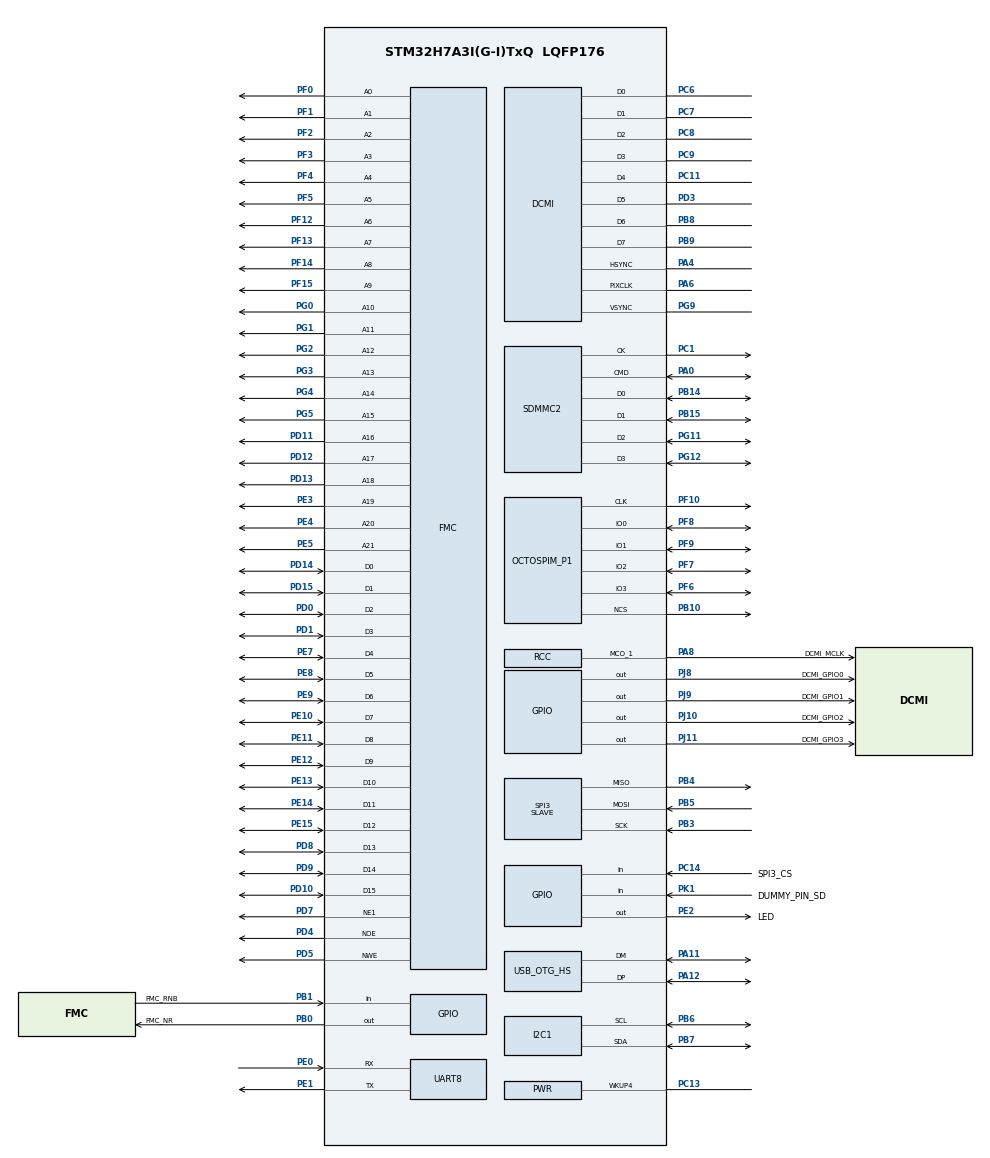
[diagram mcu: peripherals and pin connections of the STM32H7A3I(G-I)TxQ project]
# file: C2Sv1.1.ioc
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CORTEX_M7.AccessPermission_Spec=MPU_REGION_FULL_ACCESS
CORTEX_M7.BaseAddress_Spec=0x60000000
CORTEX_M7.CPU_ICache=Enabled
CORTEX_M7.DisableExec_Spec=MPU_INSTRUCTION_ACCESS_ENABLE
CORTEX_M7.IsBufferable_Spec=MPU_ACCESS_NOT_BUFFERABLE
CORTEX_M7.Size_Spec=MPU_REGION_SIZE_8MB
CORTEX_M7.SubRegionDisable_Spec=0x00
CORTEX_M7.default_mode_Activation=1
DCMI.PCKPolarity=DCMI_PCKPOLARITY_RISING
DCMI.VSPolarity=DCMI_VSPOLARITY_HIGH
Dma.DCMI.0.Direction=DMA_PERIPH_TO_MEMORY
Dma.DCMI.0.EventEnable=DISABLE
Dma.DCMI.0.FIFOMode=DMA_FIFOMODE_ENABLE
Dma.DCMI.0.FIFOThreshold=DMA_FIFO_THRESHOLD_FULL
Dma.DCMI.0.Instance=DMA1_Stream0
Dma.DCMI.0.MemBurst=DMA_MBURST_SINGLE
Dma.DCMI.0.MemDataAlignment=DMA_MDATAALIGN_WORD
Dma.DCMI.0.MemInc=DMA_MINC_ENABLE
Dma.DCMI.0.Mode=DMA_CIRCULAR
Dma.DCMI.0.PeriphBurst=DMA_PBURST_SINGLE
Dma.DCMI.0.PeriphDataAlignment=DMA_PDATAALIGN_WORD
Dma.DCMI.0.PeriphInc=DMA_PINC_DISABLE
Dma.DCMI.0.Polarity=HAL_DMAMUX_REQ_GEN_RISING
Dma.DCMI.0.Priority=DMA_PRIORITY_VERY_HIGH
Dma.DCMI.0.RequestNumber=1
Dma.DCMI.0.SignalID=NONE
Dma.DCMI.0.SyncEnable=DISABLE
Dma.DCMI.0.SyncPolarity=HAL_DMAMUX_SYNC_NO_EVENT
Dma.DCMI.0.SyncRequestNumber=1
Dma.DCMI.0.SyncSignalID=NONE
Dma.Request0=DCMI
FATFS.BSP.number=1
FATFS._MAX_SS=512
FATFS._USE_LFN=2
FATFS0.BSP.STBoard=false
FATFS0.BSP.api=Unknown
FATFS0.BSP.instance=PK1
FATFS0.BSP.ip=GPIO
FATFS0.BSP.mode=Input
FATFS0.BSP.name=Detect_SDIO
FATFS0.BSP.solution=PK1
FMC.WriteOperation1=FMC_WRITE_OPERATION_DISABLE
FREERTOS.Tasks01=defaultTask,24,128,StartDefaultTask,Default,NULL,Dynamic,NULL,NULL;comms,32,768,commsTask,Default,NULL,Dynamic,NULL,NULL;housekeeping,24,512,housekeepingTask,Default,NULL,Dynamic,NULL,NULL;imaging,16,1024,imagingTask,Default,NULL,Dynamic,NULL,NULL;imageReq,8,128,imageHkReqTask,Default,NULL,Dynamic,NULL,NULL
FREERTOS.configCHECK_FOR_STACK_OVERFLOW=2
FREERTOS.configTOTAL_HEAP_SIZE=64000
FREERTOS.configUSE_MALLOC_FAILED_HOOK=1
FREERTOS.configUSE_NEWLIB_REENTRANT=1
I2C1.Timing=0x10808DD3
JPEG.JPEG_RGB_FORMAT=JPEG_RGB565
JPEG.USE_JPEG_DECODER=0
Mcu.Family=STM32H7
Mcu.Name=STM32H7A3I(G-I)TxQ
Mcu.Package=LQFP176
NVIC.DCMI_PSSI_IRQn=true\:6\:0\:true\:false\:true\:true\:true\:true\:true
NVIC.DMA1_Stream0_IRQn=true\:6\:0\:true\:false\:true\:true\:false\:true\:true
NVIC.JPEG_IRQn=true\:7\:0\:true\:false\:true\:true\:true\:true\:true
NVIC.OTG_HS_IRQn=true\:7\:0\:true\:false\:true\:true\:false\:true\:true
NVIC.PriorityGroup=NVIC_PRIORITYGROUP_4
NVIC.SDMMC2_IRQn=true\:5\:0\:false\:false\:true\:true\:true\:true\:true
NVIC.SPI3_IRQn=true\:5\:0\:false\:false\:true\:true\:true\:true\:true
NVIC.TIM17_IRQn=true\:5\:0\:false\:false\:true\:false\:true\:true\:true
NVIC.TIM1_UP_IRQn=true\:15\:0\:false\:false\:true\:false\:false\:true\:true
NVIC.TimeBase=TIM1_UP_IRQn
NVIC.TimeBaseIP=TIM1
OCTOSPI1.ChipSelectHighTime=3
OCTOSPI1.ClockPrescaler=64
OCTOSPI1.DeviceSize=24
OCTOSPI1.SampleShifting=HAL_OSPI_SAMPLE_SHIFTING_NONE
PA0.GPIO_PuPd=GPIO_PULLUP
PA0.GPIO_Speed_High_Default=GPIO_SPEED_FREQ_VERY_HIGH
PA0.Mode=SD_4_bits_Wide_bus
PA0.Signal=SDMMC2_CMD
PA11.Mode=Device_Only_FS
PA11.Signal=USB_OTG_HS_DM
PA12.Mode=Device_Only_FS
PA12.Signal=USB_OTG_HS_DP
PA13.Mode=Serial_Wire
PA13.Signal=DEBUG_JTMS-SWDIO
PA14.Mode=Serial_Wire
PA14.Signal=DEBUG_JTCK-SWCLK
PA4.GPIO_PuPd=GPIO_PULLDOWN
PA4.GPIO_Speed=GPIO_SPEED_FREQ_VERY_HIGH
PA4.Mode=Slave_8_bits_External_Synchro
PA4.Signal=DCMI_HSYNC
PA6.GPIO_PuPd=GPIO_PULLDOWN
PA6.GPIO_Speed=GPIO_SPEED_FREQ_VERY_HIGH
PA6.Mode=Slave_8_bits_External_Synchro
PA6.Signal=DCMI_PIXCLK
PA8.GPIO_Label=DCMI_MCLK
PA8.Mode=Clock-out-1
PA8.Signal=RCC_MCO_1
PB0.GPIO_Label=FMC_NR
PB0.Signal=GPIO_Output
PB1.GPIO_Label=FMC_RNB
PB1.GPIO_PuPd=GPIO_PULLUP
PB1.Signal=GPIO_Input
PB10.Mode=OCTOSPI1_Port1_NCS
PB10.Signal=OCTOSPIM_P1_NCS
PB14.GPIO_PuPd=GPIO_PULLUP
PB14.GPIO_Speed_High_Default=GPIO_SPEED_FREQ_VERY_HIGH
PB14.Mode=SD_4_bits_Wide_bus
PB14.Signal=SDMMC2_D0
PB15.GPIO_PuPd=GPIO_PULLUP
PB15.GPIO_Speed_High_Default=GPIO_SPEED_FREQ_VERY_HIGH
PB15.Mode=SD_4_bits_Wide_bus
PB15.Signal=SDMMC2_D1
PB3.Mode=Full_Duplex_Slave
PB3.Signal=SPI3_SCK
PB4.Mode=Full_Duplex_Slave
PB4.Signal=SPI3_MISO
PB5.Mode=Full_Duplex_Slave
PB5.Signal=SPI3_MOSI
PB6.GPIO_Pu=GPIO_PULLUP
PB6.Mode=I2C
PB6.Signal=I2C1_SCL
PB7.GPIO_Pu=GPIO_PULLUP
PB7.Mode=I2C
PB7.Signal=I2C1_SDA
PB8.GPIO_PuPd=GPIO_PULLDOWN
PB8.GPIO_Speed=GPIO_SPEED_FREQ_VERY_HIGH
PB8.Mode=Slave_8_bits_External_Synchro
PB8.Signal=DCMI_D6
PB9.GPIO_PuPd=GPIO_PULLDOWN
PB9.GPIO_Speed=GPIO_SPEED_FREQ_VERY_HIGH
PB9.Mode=Slave_8_bits_External_Synchro
PB9.Signal=DCMI_D7
PC1.GPIO_PuPd=GPIO_PULLUP
PC1.GPIO_Speed_High_Default=GPIO_SPEED_FREQ_VERY_HIGH
PC1.Mode=SD_4_bits_Wide_bus
PC1.Signal=SDMMC2_CK
PC11.GPIO_PuPd=GPIO_PULLDOWN
PC11.GPIO_Speed=GPIO_SPEED_FREQ_VERY_HIGH
PC11.Mode=Slave_8_bits_External_Synchro
PC11.Signal=DCMI_D4
PC13.Mode=WakeUp4
PC13.Signal=PWR_WKUP4
PC14-OSC32_IN.GPIO_Label=SPI3_CS
PC14-OSC32_IN.Signal=GPIO_Input
PC6.GPIO_PuPd=GPIO_PULLDOWN
PC6.GPIO_Speed=GPIO_SPEED_FREQ_VERY_HIGH
PC6.Mode=Slave_8_bits_External_Synchro
PC6.Signal=DCMI_D0
PC7.GPIO_PuPd=GPIO_PULLDOWN
PC7.GPIO_Speed=GPIO_SPEED_FREQ_VERY_HIGH
PC7.Mode=Slave_8_bits_External_Synchro
PC7.Signal=DCMI_D1
PC8.GPIO_PuPd=GPIO_PULLDOWN
PC8.GPIO_Speed=GPIO_SPEED_FREQ_VERY_HIGH
PC8.Mode=Slave_8_bits_External_Synchro
PC8.Signal=DCMI_D2
PC9.GPIO_PuPd=GPIO_PULLDOWN
PC9.GPIO_Speed=GPIO_SPEED_FREQ_VERY_HIGH
PC9.Mode=Slave_8_bits_External_Synchro
PC9.Signal=DCMI_D3
PD0.Signal=FMC_D2_DA2
PD1.Signal=FMC_D3_DA3
PD10.Signal=FMC_D15_DA15
PD11.Signal=FMC_A16_CLE
PD12.Signal=FMC_A17_ALE
PD13.Signal=FMC_A18
PD14.Signal=FMC_D0_DA0
PD15.Signal=FMC_D1_DA1
PD2.GPIO_PuPd=GPIO_PULLDOWN
PD2.GPIO_Speed=GPIO_SPEED_FREQ_VERY_HIGH
PD2.Signal=DCMI_D11
PD3.GPIO_PuPd=GPIO_PULLDOWN
PD3.GPIO_Speed=GPIO_SPEED_FREQ_VERY_HIGH
PD3.Mode=Slave_8_bits_External_Synchro
PD3.Signal=DCMI_D5
PD4.Signal=FMC_NOE
PD5.Signal=FMC_NWE
PD7.Mode=NorPsramChipSelect1_1
PD7.Signal=FMC_NE1
PD8.Signal=FMC_D13_DA13
PD9.Signal=FMC_D14_DA14
PE0.Mode=Asynchronous
PE0.Signal=UART8_RX
PE1.Mode=Asynchronous
PE1.Signal=UART8_TX
PE10.Signal=FMC_D7_DA7
PE11.Signal=FMC_D8_DA8
PE12.Signal=FMC_D9_DA9
PE13.Signal=FMC_D10_DA10
PE14.Signal=FMC_D11_DA11
PE15.Signal=FMC_D12_DA12
PE2.GPIO_Label=LED
PE2.Signal=GPIO_Output
PE3.Signal=FMC_A19
PE4.Signal=FMC_A20
PE5.Signal=FMC_A21
PE7.Signal=FMC_D4_DA4
PE8.Signal=FMC_D5_DA5
PE9.Signal=FMC_D6_DA6
PF0.Signal=FMC_A0
PF1.Signal=FMC_A1
PF10.Mode=O1_P1_CLK
PF10.Signal=OCTOSPIM_P1_CLK
PF12.Signal=FMC_A6
PF13.Signal=FMC_A7
PF14.Signal=FMC_A8
PF15.Signal=FMC_A9
PF2.Signal=FMC_A2
PF3.Signal=FMC_A3
PF4.Signal=FMC_A4
PF5.Signal=FMC_A5
PF6.Mode=OCTOSPI1_IOL_Port1L
PF6.Signal=OCTOSPIM_P1_IO3
PF7.Mode=OCTOSPI1_IOL_Port1L
PF7.Signal=OCTOSPIM_P1_IO2
PF8.Mode=OCTOSPI1_IOL_Port1L
PF8.Signal=OCTOSPIM_P1_IO0
PF9.Mode=OCTOSPI1_IOL_Port1L
PF9.Signal=OCTOSPIM_P1_IO1
PG0.Signal=FMC_A10
PG1.Signal=FMC_A11
PG11.GPIO_PuPd=GPIO_PULLUP
PG11.GPIO_Speed_High_Default=GPIO_SPEED_FREQ_VERY_HIGH
PG11.Mode=SD_4_bits_Wide_bus
PG11.Signal=SDMMC2_D2
PG12.GPIO_PuPd=GPIO_PULLUP
PG12.GPIO_Speed_High_Default=GPIO_SPEED_FREQ_VERY_HIGH
PG12.Mode=SD_4_bits_Wide_bus
PG12.Signal=SDMMC2_D3
PG2.Signal=FMC_A12
PG3.Signal=FMC_A13
PG4.Signal=FMC_A14_BA0
PG5.Signal=FMC_A15_BA1
PG6.Signal=DCMI_D12
PG7.Signal=DCMI_D13
PG9.GPIO_PuPd=GPIO_PULLDOWN
PG9.GPIO_Speed=GPIO_SPEED_FREQ_VERY_HIGH
PG9.Mode=Slave_8_bits_External_Synchro
PG9.Signal=DCMI_VSYNC
PH0-OSC_IN.Mode=HSE-External-Clock-Source
PH0-OSC_IN.Signal=RCC_OSC_IN
PJ10.GPIO_Label=DCMI_GPIO2
PJ10.Signal=GPIO_Output
PJ11.GPIO_Label=DCMI_GPIO3
PJ11.Signal=GPIO_Output
PJ8.GPIO_Label=DCMI_GPIO0
PJ8.Signal=GPIO_Output
PJ9.GPIO_Label=DCMI_GPIO1
PJ9.Signal=GPIO_Output
PK1.GPIO_Label=DUMMY_PIN_SD
PK1.GPIO_PuPd=GPIO_PULLDOWN
PK1.Signal=GPIO_Input
ProjectManager.HeapSize=0x200
ProjectManager.StackSize=0x400
ProjectManager.TargetToolchain=STM32CubeIDE
RCC.ADCFreq_Value=132000000
RCC.APB1Freq_Value=140000000
RCC.APB2Freq_Value=140000000
RCC.APB3Freq_Value=140000000
RCC.APB4Freq_Value=140000000
RCC.CDPPRE=RCC_APB3_DIV2
RCC.CDPPRE1=RCC_APB1_DIV2
RCC.CDPPRE2=RCC_APB2_DIV2
RCC.CortexFreq_Value=280000000
RCC.DIVM1=3
RCC.DIVM2=2
RCC.DIVM3=2
RCC.DIVN1=70
RCC.DIVN2=11
RCC.DIVN3=12
RCC.DIVP2=1
RCC.DIVP3=1
RCC.DIVQ2=1
RCC.DIVQ3=3
RCC.DIVR2=1
RCC.EnbaleCSS=true
RCC.FMCCLockSelection=RCC_FMCCLKSOURCE_PLL2
RCC.HCLKFreq_Value=280000000
RCC.I2C123CLockSelection=RCC_I2C123CLKSOURCE_PLL3
RCC.PLL2FRACN=0
RCC.PLL3FRACN=0
RCC.PLLFRACN=0
RCC.PLLSourceVirtual=RCC_PLLSOURCE_HSE
RCC.PWR_Regulator_Voltage_Scale=PWR_REGULATOR_VOLTAGE_SCALE0
RCC.RCC_MCO1Source=RCC_MCO1SOURCE_HSE
RCC.SDMMC1CLockSelection=RCC_SDMMCCLKSOURCE_PLL2
RCC.SRDPPRE=RCC_APB4_DIV2
RCC.SYSCLKFreq_VALUE=280000000
RCC.SYSCLKSource=RCC_SYSCLKSOURCE_PLLCLK
RCC.SupplySource=PWR_LDO_SUPPLY
RCC.USBCLockSelection=RCC_USBCLKSOURCE_PLL3
RCC.USBFreq_Value=48000000
SDMMC2.ClockDiv=8
SH.FMC_A0.0=FMC_A0,22b-a1
SH.FMC_A1.0=FMC_A1,22b-a1
SH.FMC_A10.0=FMC_A10,22b-a1
SH.FMC_A11.0=FMC_A11,22b-a1
SH.FMC_A12.0=FMC_A12,22b-a1
SH.FMC_A13.0=FMC_A13,22b-a1
SH.FMC_A14_BA0.0=FMC_A14,22b-a1
SH.FMC_A15_BA1.0=FMC_A15,22b-a1
SH.FMC_A16_CLE.0=FMC_A16,22b-a1
SH.FMC_A17_ALE.0=FMC_A17,22b-a1
SH.FMC_A18.0=FMC_A18,22b-a1
SH.FMC_A19.0=FMC_A19,22b-a1
SH.FMC_A2.0=FMC_A2,22b-a1
SH.FMC_A20.0=FMC_A20,22b-a1
SH.FMC_A21.0=FMC_A21,22b-a1
SH.FMC_A3.0=FMC_A3,22b-a1
SH.FMC_A4.0=FMC_A4,22b-a1
SH.FMC_A5.0=FMC_A5,22b-a1
SH.FMC_A6.0=FMC_A6,22b-a1
SH.FMC_A7.0=FMC_A7,22b-a1
SH.FMC_A8.0=FMC_A8,22b-a1
SH.FMC_A9.0=FMC_A9,22b-a1
SH.FMC_D0_DA0.0=FMC_D0,16b-d1
SH.FMC_D10_DA10.0=FMC_D10,16b-d1
SH.FMC_D11_DA11.0=FMC_D11,16b-d1
SH.FMC_D12_DA12.0=FMC_D12,16b-d1
SH.FMC_D13_DA13.0=FMC_D13,16b-d1
SH.FMC_D14_DA14.0=FMC_D14,16b-d1
SH.FMC_D15_DA15.0=FMC_D15,16b-d1
SH.FMC_D1_DA1.0=FMC_D1,16b-d1
SH.FMC_D2_DA2.0=FMC_D2,16b-d1
SH.FMC_D3_DA3.0=FMC_D3,16b-d1
SH.FMC_D4_DA4.0=FMC_D4,16b-d1
SH.FMC_D5_DA5.0=FMC_D5,16b-d1
SH.FMC_D6_DA6.0=FMC_D6,16b-d1
SH.FMC_D7_DA7.0=FMC_D7,16b-d1
SH.FMC_D8_DA8.0=FMC_D8,16b-d1
SH.FMC_D9_DA9.0=FMC_D9,16b-d1
SH.FMC_NOE.0=FMC_NOE,NorFlash1
SH.FMC_NWE.0=FMC_NWE,NorFlash1
SPI3.DataSize=SPI_DATASIZE_8BIT
SPI3.Direction=SPI_DIRECTION_2LINES
SPI3.Mode=SPI_MODE_SLAVE
SPI3.VirtualType=VM_SLAVE
TIM17.Period=45-1
TIM17.Prescaler=1
USB_DEVICE.CLASS_NAME_HS=CDC
USB_DEVICE.MANUFACTURER_STRING=Perth Aerosapce Student Team
USB_DEVICE.PRODUCT_STRING_CDC_HS=C2Sv1.1
USB_DEVICE.VirtualMode=Cdc
USB_DEVICE.VirtualModeHS=Cdc_HS
USB_OTG_HS.VirtualMode-Device_Only_FS=Device_Only_FS
VP_FATFS_VS_SDIO.Mode=SDIO
VP_FREERTOS_VS_CMSIS_V2.Mode=CMSIS_V2
VP_JPEG_VS_JPEG.Mode=JPEG_Activate
VP_MEMORYMAP_VS_MEMORYMAP.Mode=CurAppReg
VP_OCTOSPI1_VS_quad.Mode=quad_mode
VP_SYS_VS_tim1.Mode=TIM1
VP_TIM17_VS_ClockSourceINT.Mode=Enable_Timer
VP_TIM17_VS_OPM.Mode=OPM_bit
VP_USB_DEVICE_VS_USB_DEVICE_CDC_HS.Mode=CDC_HS
board=custom

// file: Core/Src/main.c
/* USER CODE BEGIN Header */
/**
  ******************************************************************************
  * @file           : main.c
  * @brief          : Main program body
  ******************************************************************************
  * @attention
  *
  * Copyright (c) 2026 STMicroelectronics.
  * All rights reserved.
  *
  * This software is licensed under terms that can be found in the LICENSE file
  * in the root directory of this software component.
  * If no LICENSE file comes with this software, it is provided AS-IS.
  *
  ******************************************************************************
  */
/* USER CODE END Header */
#include "main.h"
#include "FreeRTOS.h"
#include "cmsis_os2.h"
#include "fatfs.h"
#include "usb_device.h"

/* USER CODE BEGIN Includes */

#include "dashboard.h"
#include "img_jpeg.h"
#include "imaging.h"
#include "comms.h"
#include "config.h"
#include "ina219.h"
#include "ov7670.h"
#include "rgb_led.h"
#include "microSD.h"
#include "task.h"

/* USER CODE END Includes */

DCMI_HandleTypeDef hdcmi;
DMA_HandleTypeDef hdma_dcmi;

I2C_HandleTypeDef hi2c1;

JPEG_HandleTypeDef hjpeg;

OSPI_HandleTypeDef hospi1;

SD_HandleTypeDef hsd2;

SPI_HandleTypeDef hspi3;

TIM_HandleTypeDef htim17;

UART_HandleTypeDef huart8;

NOR_HandleTypeDef hnor1;

/* Definitions for defaultTask */
osThreadId_t defaultTaskHandle;
const osThreadAttr_t defaultTask_attributes = {
  .name = "defaultTask",
  .stack_size = 128 * 4,
  .priority = (osPriority_t) osPriorityNormal,
};
/* Definitions for comms */
osThreadId_t commsHandle;
const osThreadAttr_t comms_attributes = {
  .name = "comms",
  .stack_size = 768 * 4,
  .priority = (osPriority_t) osPriorityAboveNormal,
};
/* Definitions for housekeeping */
osThreadId_t housekeepingHandle;
const osThreadAttr_t housekeeping_attributes = {
  .name = "housekeeping",
  .stack_size = 512 * 4,
  .priority = (osPriority_t) osPriorityNormal,
};
/* Definitions for imaging */
osThreadId_t imagingHandle;
const osThreadAttr_t imaging_attributes = {
  .name = "imaging",
  .stack_size = 1024 * 4,
  .priority = (osPriority_t) osPriorityBelowNormal,
};
/* Definitions for imageReq */
osThreadId_t imageReqHandle;
const osThreadAttr_t imageReq_attributes = {
  .name = "imageReq",
  .stack_size = 128 * 4,
  .priority = (osPriority_t) osPriorityLow,
};
/* USER CODE BEGIN PV */

// --- INA219 ---
CSA_HandleTypeDef csa;

// --- DCMI ---
// Static, not a local in main(): FreeRTOS reuses main()'s stack for
// interrupts once the scheduler starts, so DMA into it would corrupt memory.
// Sized for VGA, the largest frame the dashboard requests (614 KB in AXI SRAM).
ALIGN_32BYTES(uint32_t pBuffer[VGA_IMAGE_SIZE_WORDS]);

// -- IMAGING ---
extern volatile imaging_req_t g_imaging_req;

/* USER CODE END PV */

void SystemClock_Config(void);
void PeriphCommonClock_Config(void);
static void MPU_Config(void);
static void MX_GPIO_Init(void);
static void MX_DMA_Init(void);
static void MX_DCMI_Init(void);
static void MX_FMC_Init(void);
static void MX_I2C1_Init(void);
static void MX_OCTOSPI1_Init(void);
static void MX_SDMMC2_SD_Init(void);
static void MX_SPI3_Init(void);
static void MX_UART8_Init(void);
static void MX_TIM17_Init(void);
static void MX_JPEG_Init(void);
void StartDefaultTask(void *argument);
void commsTask(void *argument);
void housekeepingTask(void *argument);
void imagingTask(void *argument);
void imageHkReqTask(void *argument);

int main(void)
{

  /* MPU Configuration--------------------------------------------------------*/
  MPU_Config();

  /* Enable the CPU Cache */

  /* Enable I-Cache---------------------------------------------------------*/
  SCB_EnableICache();

  /* MCU Configuration--------------------------------------------------------*/

  /* Reset of all peripherals, Initializes the Flash interface and the Systick. */
  HAL_Init();

  /* Configure the system clock */
  SystemClock_Config();

  /* Configure the peripherals common clocks */
  PeriphCommonClock_Config();

  /* Initialize all configured peripherals */
  MX_GPIO_Init();
  MX_DMA_Init();
  MX_DCMI_Init();
  MX_FMC_Init();
  MX_I2C1_Init();
  MX_OCTOSPI1_Init();
  MX_SDMMC2_SD_Init();
  MX_SPI3_Init();
  MX_UART8_Init();
  MX_FATFS_Init();
  MX_TIM17_Init();
  MX_JPEG_Init();

  /* Init scheduler */
  osKernelInitialize();

  /* Create the thread(s) */
  /* creation of defaultTask */
  defaultTaskHandle = osThreadNew(StartDefaultTask, NULL, &defaultTask_attributes);

  /* creation of comms */
  commsHandle = osThreadNew(commsTask, NULL, &comms_attributes);

  /* creation of housekeeping */
  housekeepingHandle = osThreadNew(housekeepingTask, NULL, &housekeeping_attributes);

  /* creation of imaging */
  imagingHandle = osThreadNew(imagingTask, NULL, &imaging_attributes);

  /* creation of imageReq */
  imageReqHandle = osThreadNew(imageHkReqTask, NULL, &imageReq_attributes);

  /* Start scheduler */
  osKernelStart();

  /* We should never get here as control is now taken by the scheduler */

  /* Infinite loop */
  while (1)
  {

  }
}

void SystemClock_Config(void)
{
  RCC_OscInitTypeDef RCC_OscInitStruct = {0};
  RCC_ClkInitTypeDef RCC_ClkInitStruct = {0};

  /*AXI clock gating */
  RCC->CKGAENR = 0xE003FFFF;

  /** Supply configuration update enable
  */
  HAL_PWREx_ConfigSupply(PWR_LDO_SUPPLY);

  /** Configure the main internal regulator output voltage
  */
  __HAL_PWR_VOLTAGESCALING_CONFIG(PWR_REGULATOR_VOLTAGE_SCALE0);

  while(!__HAL_PWR_GET_FLAG(PWR_FLAG_VOSRDY)) {}

  /** Initializes the RCC Oscillators according to the specified parameters
  * in the RCC_OscInitTypeDef structure.
  */
  RCC_OscInitStruct.OscillatorType = RCC_OSCILLATORTYPE_HSE;
  RCC_OscInitStruct.HSEState = RCC_HSE_BYPASS;
  RCC_OscInitStruct.PLL.PLLState = RCC_PLL_ON;
  RCC_OscInitStruct.PLL.PLLSource = RCC_PLLSOURCE_HSE;
  RCC_OscInitStruct.PLL.PLLM = 3;
  RCC_OscInitStruct.PLL.PLLN = 70;
  RCC_OscInitStruct.PLL.PLLP = 2;
  RCC_OscInitStruct.PLL.PLLQ = 2;
  RCC_OscInitStruct.PLL.PLLR = 2;
  RCC_OscInitStruct.PLL.PLLRGE = RCC_PLL1VCIRANGE_3;
  RCC_OscInitStruct.PLL.PLLVCOSEL = RCC_PLL1VCOWIDE;
  RCC_OscInitStruct.PLL.PLLFRACN = 0;
  if (HAL_RCC_OscConfig(&RCC_OscInitStruct) != HAL_OK)
  {
    Error_Handler();
  }

  /** Initializes the CPU, AHB and APB buses clocks
  */
  RCC_ClkInitStruct.ClockType = RCC_CLOCKTYPE_HCLK|RCC_CLOCKTYPE_SYSCLK
                              |RCC_CLOCKTYPE_PCLK1|RCC_CLOCKTYPE_PCLK2
                              |RCC_CLOCKTYPE_D3PCLK1|RCC_CLOCKTYPE_D1PCLK1;
  RCC_ClkInitStruct.SYSCLKSource = RCC_SYSCLKSOURCE_PLLCLK;
  RCC_ClkInitStruct.SYSCLKDivider = RCC_SYSCLK_DIV1;
  RCC_ClkInitStruct.AHBCLKDivider = RCC_HCLK_DIV1;
  RCC_ClkInitStruct.APB3CLKDivider = RCC_APB3_DIV2;
  RCC_ClkInitStruct.APB1CLKDivider = RCC_APB1_DIV2;
  RCC_ClkInitStruct.APB2CLKDivider = RCC_APB2_DIV2;
  RCC_ClkInitStruct.APB4CLKDivider = RCC_APB4_DIV2;

  if (HAL_RCC_ClockConfig(&RCC_ClkInitStruct, FLASH_LATENCY_6) != HAL_OK)
  {
    Error_Handler();
  }
  HAL_RCC_MCOConfig(RCC_MCO1, RCC_MCO1SOURCE_HSE, RCC_MCODIV_1);

  /** Enables the Clock Security System
  */
  HAL_RCC_EnableCSS();
}

void PeriphCommonClock_Config(void)
{
  RCC_PeriphCLKInitTypeDef PeriphClkInitStruct = {0};

  /** Initializes the peripherals clock
  */
  PeriphClkInitStruct.PeriphClockSelection = RCC_PERIPHCLK_FMC|RCC_PERIPHCLK_USB
                              |RCC_PERIPHCLK_I2C1|RCC_PERIPHCLK_SDMMC;
  PeriphClkInitStruct.PLL2.PLL2M = 2;
  PeriphClkInitStruct.PLL2.PLL2N = 11;
  PeriphClkInitStruct.PLL2.PLL2P = 1;
  PeriphClkInitStruct.PLL2.PLL2Q = 1;
  PeriphClkInitStruct.PLL2.PLL2R = 1;
  PeriphClkInitStruct.PLL2.PLL2RGE = RCC_PLL2VCIRANGE_3;
  PeriphClkInitStruct.PLL2.PLL2VCOSEL = RCC_PLL2VCOWIDE;
  PeriphClkInitStruct.PLL2.PLL2FRACN = 0;
  PeriphClkInitStruct.PLL3.PLL3M = 2;
  PeriphClkInitStruct.PLL3.PLL3N = 12;
  PeriphClkInitStruct.PLL3.PLL3P = 1;
  PeriphClkInitStruct.PLL3.PLL3Q = 3;
  PeriphClkInitStruct.PLL3.PLL3R = 2;
  PeriphClkInitStruct.PLL3.PLL3RGE = RCC_PLL3VCIRANGE_3;
  PeriphClkInitStruct.PLL3.PLL3VCOSEL = RCC_PLL3VCOWIDE;
  PeriphClkInitStruct.PLL3.PLL3FRACN = 0;
  PeriphClkInitStruct.FmcClockSelection = RCC_FMCCLKSOURCE_PLL2;
  PeriphClkInitStruct.SdmmcClockSelection = RCC_SDMMCCLKSOURCE_PLL2;
  PeriphClkInitStruct.I2c123ClockSelection = RCC_I2C123CLKSOURCE_PLL3;
  PeriphClkInitStruct.UsbClockSelection = RCC_USBCLKSOURCE_PLL3;
  if (HAL_RCCEx_PeriphCLKConfig(&PeriphClkInitStruct) != HAL_OK)
  {
    Error_Handler();
  }
}

static void MX_DCMI_Init(void)
{

  hdcmi.Instance = DCMI;
  hdcmi.Init.SynchroMode = DCMI_SYNCHRO_HARDWARE;
  hdcmi.Init.PCKPolarity = DCMI_PCKPOLARITY_RISING;
  hdcmi.Init.VSPolarity = DCMI_VSPOLARITY_HIGH;
  hdcmi.Init.HSPolarity = DCMI_HSPOLARITY_LOW;
  hdcmi.Init.CaptureRate = DCMI_CR_ALL_FRAME;
  hdcmi.Init.ExtendedDataMode = DCMI_EXTEND_DATA_8B;
  hdcmi.Init.JPEGMode = DCMI_JPEG_DISABLE;
  hdcmi.Init.ByteSelectMode = DCMI_BSM_ALL;
  hdcmi.Init.ByteSelectStart = DCMI_OEBS_ODD;
  hdcmi.Init.LineSelectMode = DCMI_LSM_ALL;
  hdcmi.Init.LineSelectStart = DCMI_OELS_ODD;
  if (HAL_DCMI_Init(&hdcmi) != HAL_OK)
  {
    Error_Handler();
  }

}

static void MX_I2C1_Init(void)
{

  hi2c1.Instance = I2C1;
  hi2c1.Init.Timing = 0x10808DD3;
  hi2c1.Init.OwnAddress1 = 0;
  hi2c1.Init.AddressingMode = I2C_ADDRESSINGMODE_7BIT;
  hi2c1.Init.DualAddressMode = I2C_DUALADDRESS_DISABLE;
  hi2c1.Init.OwnAddress2 = 0;
  hi2c1.Init.OwnAddress2Masks = I2C_OA2_NOMASK;
  hi2c1.Init.GeneralCallMode = I2C_GENERALCALL_DISABLE;
  hi2c1.Init.NoStretchMode = I2C_NOSTRETCH_DISABLE;
  if (HAL_I2C_Init(&hi2c1) != HAL_OK)
  {
    Error_Handler();
  }

  /** Configure Analogue filter
  */
  if (HAL_I2CEx_ConfigAnalogFilter(&hi2c1, I2C_ANALOGFILTER_ENABLE) != HAL_OK)
  {
    Error_Handler();
  }

  /** Configure Digital filter
  */
  if (HAL_I2CEx_ConfigDigitalFilter(&hi2c1, 0) != HAL_OK)
  {
    Error_Handler();
  }

}

static void MX_JPEG_Init(void)
{

  hjpeg.Instance = JPEG;
  if (HAL_JPEG_Init(&hjpeg) != HAL_OK)
  {
    Error_Handler();
  }

}

static void MX_OCTOSPI1_Init(void)
{

  OSPIM_CfgTypeDef sOspiManagerCfg = {0};

  /* OCTOSPI1 parameter configuration*/
  hospi1.Instance = OCTOSPI1;
  hospi1.Init.FifoThreshold = 1;
  hospi1.Init.DualQuad = HAL_OSPI_DUALQUAD_DISABLE;
  hospi1.Init.MemoryType = HAL_OSPI_MEMTYPE_MICRON;
  hospi1.Init.DeviceSize = 24;
  hospi1.Init.ChipSelectHighTime = 3;
  hospi1.Init.FreeRunningClock = HAL_OSPI_FREERUNCLK_DISABLE;
  hospi1.Init.ClockMode = HAL_OSPI_CLOCK_MODE_0;
  hospi1.Init.WrapSize = HAL_OSPI_WRAP_NOT_SUPPORTED;
  hospi1.Init.ClockPrescaler = 64;
  hospi1.Init.SampleShifting = HAL_OSPI_SAMPLE_SHIFTING_NONE;
  hospi1.Init.DelayHoldQuarterCycle = HAL_OSPI_DHQC_DISABLE;
  hospi1.Init.ChipSelectBoundary = 0;
  hospi1.Init.DelayBlockBypass = HAL_OSPI_DELAY_BLOCK_BYPASSED;
  hospi1.Init.MaxTran = 0;
  hospi1.Init.Refresh = 0;
  if (HAL_OSPI_Init(&hospi1) != HAL_OK)
  {
    Error_Handler();
  }
  sOspiManagerCfg.ClkPort = 1;
  sOspiManagerCfg.NCSPort = 1;
  sOspiManagerCfg.IOLowPort = HAL_OSPIM_IOPORT_1_LOW;
  if (HAL_OSPIM_Config(&hospi1, &sOspiManagerCfg, HAL_OSPI_TIMEOUT_DEFAULT_VALUE) != HAL_OK)
  {
    Error_Handler();
  }

}

static void MX_SDMMC2_SD_Init(void)
{

  hsd2.Instance = SDMMC2;
  hsd2.Init.ClockEdge = SDMMC_CLOCK_EDGE_RISING;
  hsd2.Init.ClockPowerSave = SDMMC_CLOCK_POWER_SAVE_DISABLE;
  hsd2.Init.BusWide = SDMMC_BUS_WIDE_4B;
  hsd2.Init.HardwareFlowControl = SDMMC_HARDWARE_FLOW_CONTROL_DISABLE;
  hsd2.Init.ClockDiv = 8;
  if (HAL_SD_Init(&hsd2) != HAL_OK)
  {
    Error_Handler();
  }

}

static void MX_SPI3_Init(void)
{

  /* SPI3 parameter configuration*/
  hspi3.Instance = SPI3;
  hspi3.Init.Mode = SPI_MODE_SLAVE;
  hspi3.Init.Direction = SPI_DIRECTION_2LINES;
  hspi3.Init.DataSize = SPI_DATASIZE_8BIT;
  hspi3.Init.CLKPolarity = SPI_POLARITY_LOW;
  hspi3.Init.CLKPhase = SPI_PHASE_1EDGE;
  hspi3.Init.NSS = SPI_NSS_SOFT;
  hspi3.Init.FirstBit = SPI_FIRSTBIT_MSB;
  hspi3.Init.TIMode = SPI_TIMODE_DISABLE;
  hspi3.Init.CRCCalculation = SPI_CRCCALCULATION_DISABLE;
  hspi3.Init.CRCPolynomial = 0x0;
  hspi3.Init.NSSPMode = SPI_NSS_PULSE_DISABLE;
  hspi3.Init.NSSPolarity = SPI_NSS_POLARITY_LOW;
  hspi3.Init.FifoThreshold = SPI_FIFO_THRESHOLD_01DATA;
  hspi3.Init.TxCRCInitializationPattern = SPI_CRC_INITIALIZATION_ALL_ZERO_PATTERN;
  hspi3.Init.RxCRCInitializationPattern = SPI_CRC_INITIALIZATION_ALL_ZERO_PATTERN;
  hspi3.Init.MasterSSIdleness = SPI_MASTER_SS_IDLENESS_00CYCLE;
  hspi3.Init.MasterInterDataIdleness = SPI_MASTER_INTERDATA_IDLENESS_00CYCLE;
  hspi3.Init.MasterReceiverAutoSusp = SPI_MASTER_RX_AUTOSUSP_DISABLE;
  hspi3.Init.MasterKeepIOState = SPI_MASTER_KEEP_IO_STATE_DISABLE;
  hspi3.Init.IOSwap = SPI_IO_SWAP_DISABLE;
  if (HAL_SPI_Init(&hspi3) != HAL_OK)
  {
    Error_Handler();
  }

}

static void MX_TIM17_Init(void)
{

  htim17.Instance = TIM17;
  htim17.Init.Prescaler = 1;
  htim17.Init.CounterMode = TIM_COUNTERMODE_UP;
  htim17.Init.Period = 45-1;
  htim17.Init.ClockDivision = TIM_CLOCKDIVISION_DIV1;
  htim17.Init.RepetitionCounter = 0;
  htim17.Init.AutoReloadPreload = TIM_AUTORELOAD_PRELOAD_DISABLE;
  if (HAL_TIM_Base_Init(&htim17) != HAL_OK)
  {
    Error_Handler();
  }
  if (HAL_TIM_OnePulse_Init(&htim17, TIM_OPMODE_SINGLE) != HAL_OK)
  {
    Error_Handler();
  }

}

static void MX_UART8_Init(void)
{

  huart8.Instance = UART8;
  huart8.Init.BaudRate = 115200;
  huart8.Init.WordLength = UART_WORDLENGTH_8B;
  huart8.Init.StopBits = UART_STOPBITS_1;
  huart8.Init.Parity = UART_PARITY_NONE;
  huart8.Init.Mode = UART_MODE_TX_RX;
  huart8.Init.HwFlowCtl = UART_HWCONTROL_NONE;
  huart8.Init.OverSampling = UART_OVERSAMPLING_16;
  huart8.Init.OneBitSampling = UART_ONE_BIT_SAMPLE_DISABLE;
  huart8.Init.ClockPrescaler = UART_PRESCALER_DIV1;
  huart8.AdvancedInit.AdvFeatureInit = UART_ADVFEATURE_NO_INIT;
  if (HAL_UART_Init(&huart8) != HAL_OK)
  {
    Error_Handler();
  }
  if (HAL_UARTEx_SetTxFifoThreshold(&huart8, UART_TXFIFO_THRESHOLD_1_8) != HAL_OK)
  {
    Error_Handler();
  }
  if (HAL_UARTEx_SetRxFifoThreshold(&huart8, UART_RXFIFO_THRESHOLD_1_8) != HAL_OK)
  {
    Error_Handler();
  }
  if (HAL_UARTEx_DisableFifoMode(&huart8) != HAL_OK)
  {
    Error_Handler();
  }

}

static void MX_DMA_Init(void)
{

  /* DMA controller clock enable */
  __HAL_RCC_DMA1_CLK_ENABLE();

  /* DMA interrupt init */
  /* DMA1_Stream0_IRQn interrupt configuration */
  HAL_NVIC_SetPriority(DMA1_Stream0_IRQn, 6, 0);
  HAL_NVIC_EnableIRQ(DMA1_Stream0_IRQn);

}

/* FMC initialization function */
static void MX_FMC_Init(void)
{

  FMC_NORSRAM_TimingTypeDef Timing = {0};

  /** Perform the NOR1 memory initialization sequence
  */
  hnor1.Instance = FMC_NORSRAM_DEVICE;
  hnor1.Extended = FMC_NORSRAM_EXTENDED_DEVICE;
  /* hnor1.Init */
  hnor1.Init.NSBank = FMC_NORSRAM_BANK1;
  hnor1.Init.DataAddressMux = FMC_DATA_ADDRESS_MUX_DISABLE;
  hnor1.Init.MemoryType = FMC_MEMORY_TYPE_NOR;
  hnor1.Init.MemoryDataWidth = FMC_NORSRAM_MEM_BUS_WIDTH_16;
  hnor1.Init.BurstAccessMode = FMC_BURST_ACCESS_MODE_DISABLE;
  hnor1.Init.WaitSignalPolarity = FMC_WAIT_SIGNAL_POLARITY_LOW;
  hnor1.Init.WaitSignalActive = FMC_WAIT_TIMING_BEFORE_WS;
  hnor1.Init.WriteOperation = FMC_WRITE_OPERATION_DISABLE;
  hnor1.Init.WaitSignal = FMC_WAIT_SIGNAL_DISABLE;
  hnor1.Init.ExtendedMode = FMC_EXTENDED_MODE_DISABLE;
  hnor1.Init.AsynchronousWait = FMC_ASYNCHRONOUS_WAIT_DISABLE;
  hnor1.Init.WriteBurst = FMC_WRITE_BURST_DISABLE;
  hnor1.Init.ContinuousClock = FMC_CONTINUOUS_CLOCK_SYNC_ONLY;
  hnor1.Init.WriteFifo = FMC_WRITE_FIFO_ENABLE;
  hnor1.Init.PageSize = FMC_PAGE_SIZE_NONE;
  /* Timing */
  Timing.AddressSetupTime = 15;
  Timing.AddressHoldTime = 15;
  Timing.DataSetupTime = 255;
  Timing.BusTurnAroundDuration = 15;
  Timing.CLKDivision = 16;
  Timing.DataLatency = 17;
  Timing.AccessMode = FMC_ACCESS_MODE_A;
  /* ExtTiming */

  if (HAL_NOR_Init(&hnor1, &Timing, NULL) != HAL_OK)
  {
    Error_Handler( );
  }

}

static void MX_GPIO_Init(void)
{
  GPIO_InitTypeDef GPIO_InitStruct = {0};

  /* GPIO Ports Clock Enable */
  __HAL_RCC_GPIOE_CLK_ENABLE();
  __HAL_RCC_GPIOC_CLK_ENABLE();
  __HAL_RCC_GPIOF_CLK_ENABLE();
  __HAL_RCC_GPIOH_CLK_ENABLE();
  __HAL_RCC_GPIOA_CLK_ENABLE();
  __HAL_RCC_GPIOB_CLK_ENABLE();
  __HAL_RCC_GPIOG_CLK_ENABLE();
  __HAL_RCC_GPIOD_CLK_ENABLE();
  __HAL_RCC_GPIOJ_CLK_ENABLE();
  __HAL_RCC_GPIOK_CLK_ENABLE();

  /*Configure GPIO pin Output Level */
  HAL_GPIO_WritePin(LED_GPIO_Port, LED_Pin, GPIO_PIN_RESET);

  /*Configure GPIO pin Output Level */
  HAL_GPIO_WritePin(FMC_NR_GPIO_Port, FMC_NR_Pin, GPIO_PIN_RESET);

  /*Configure GPIO pin Output Level */
  HAL_GPIO_WritePin(GPIOJ, DCMI_GPIO0_Pin|DCMI_GPIO1_Pin|DCMI_GPIO2_Pin|DCMI_GPIO3_Pin, GPIO_PIN_RESET);

  /*Configure GPIO pin : LED_Pin */
  GPIO_InitStruct.Pin = LED_Pin;
  GPIO_InitStruct.Mode = GPIO_MODE_OUTPUT_PP;
  GPIO_InitStruct.Pull = GPIO_NOPULL;
  GPIO_InitStruct.Speed = GPIO_SPEED_FREQ_LOW;
  HAL_GPIO_Init(LED_GPIO_Port, &GPIO_InitStruct);

  /*Configure GPIO pin : SPI3_CS_Pin */
  GPIO_InitStruct.Pin = SPI3_CS_Pin;
  GPIO_InitStruct.Mode = GPIO_MODE_INPUT;
  GPIO_InitStruct.Pull = GPIO_NOPULL;
  HAL_GPIO_Init(SPI3_CS_GPIO_Port, &GPIO_InitStruct);

  /*Configure GPIO pin : FMC_NR_Pin */
  GPIO_InitStruct.Pin = FMC_NR_Pin;
  GPIO_InitStruct.Mode = GPIO_MODE_OUTPUT_PP;
  GPIO_InitStruct.Pull = GPIO_NOPULL;
  GPIO_InitStruct.Speed = GPIO_SPEED_FREQ_LOW;
  HAL_GPIO_Init(FMC_NR_GPIO_Port, &GPIO_InitStruct);

  /*Configure GPIO pin : FMC_RNB_Pin */
  GPIO_InitStruct.Pin = FMC_RNB_Pin;
  GPIO_InitStruct.Mode = GPIO_MODE_INPUT;
  GPIO_InitStruct.Pull = GPIO_PULLUP;
  HAL_GPIO_Init(FMC_RNB_GPIO_Port, &GPIO_InitStruct);

  /*Configure GPIO pins : DCMI_GPIO0_Pin DCMI_GPIO1_Pin DCMI_GPIO2_Pin DCMI_GPIO3_Pin */
  GPIO_InitStruct.Pin = DCMI_GPIO0_Pin|DCMI_GPIO1_Pin|DCMI_GPIO2_Pin|DCMI_GPIO3_Pin;
  GPIO_InitStruct.Mode = GPIO_MODE_OUTPUT_PP;
  GPIO_InitStruct.Pull = GPIO_NOPULL;
  GPIO_InitStruct.Speed = GPIO_SPEED_FREQ_LOW;
  HAL_GPIO_Init(GPIOJ, &GPIO_InitStruct);

  /*Configure GPIO pin : DUMMY_PIN_SD_Pin */
  GPIO_InitStruct.Pin = DUMMY_PIN_SD_Pin;
  GPIO_InitStruct.Mode = GPIO_MODE_INPUT;
  GPIO_InitStruct.Pull = GPIO_PULLDOWN;
  HAL_GPIO_Init(DUMMY_PIN_SD_GPIO_Port, &GPIO_InitStruct);

  /*Configure GPIO pin : DCMI_MCLK_Pin */
  GPIO_InitStruct.Pin = DCMI_MCLK_Pin;
  GPIO_InitStruct.Mode = GPIO_MODE_AF_PP;
  GPIO_InitStruct.Pull = GPIO_NOPULL;
  GPIO_InitStruct.Speed = GPIO_SPEED_FREQ_LOW;
  GPIO_InitStruct.Alternate = GPIO_AF0_MCO;
  HAL_GPIO_Init(DCMI_MCLK_GPIO_Port, &GPIO_InitStruct);

}

void StartDefaultTask(void *argument)
{
  /* init code for USB_DEVICE */
  MX_USB_DEVICE_Init();
  /* USER CODE BEGIN 5 */
  /* Infinite loop */
  for(;;)
  {
    osDelay(osWaitForever);
  }
  /* USER CODE END 5 */
}

void commsTask(void *argument)
{
  /* USER CODE BEGIN commsTask */
	#if OPERATIONAL_MODE == SLAVE_MODE

		for (;;)
		{
			// If comms_run() unexpectedly returns, then restart
			comms_run();
			osDelay(10);
		}
	#else
		for (;;)
		{
			osDelay(osWaitForever);   // nothing to do in this mode; sleep forever
		}
	#endif
  /* USER CODE END commsTask */
}

void housekeepingTask(void *argument)
{
  /* USER CODE BEGIN housekeepingTask */

	#define TASK_TIMEOUT 200u
	#define VOLTAGE_ERROR_THRESH_MV 4500u 					// 4.5 Volts
	#define MICROSD_TIME_PERIOD_MS (300*configTICK_RATE_HZ)	// 5 Minute(s)

	// Create the first CSA log file
	uint8_t status = 0;
	/* status[7:0]
	 * status[0] = Voltage Error
	 * status[1] = Camera Error
	 * status[2] = microSD Mount Error
	 * status[3] = microSD Create File Error
	 * status[4] = microSD Init Error
	 * status[5] = microSD Append Error
	 * status[6] = NIL
	 * status[7] = NIL
	 */
	char filename[32];

	// Initialise
	RGB_Init();
	CSA_Setup(&csa, &hi2c1);
	OV7670_Init(&hdcmi, &hdma_dcmi, &hi2c1);

	if (microsd_mount() != HAL_OK) status |= 0x04; // Mount microSD card

	if (microsd_create_indexed_file(filename) != HAL_OK) status |= 0x08;
	if (microsd_init_file(filename) != HAL_OK) status |= 0x10;

	uint32_t prev_time = xTaskGetTickCount();

	/*
	 * Each subprocess within the for(;;) loop can take a different number of ticks between each run.
	 * The wait time between runs is goverened by a static wait time, therefore the elapsed time between housekeeping runs is inconsistent.
	 * The tick at write-time is put on the microSD card in `microsd_append_file`.
	 */

	for(;;)
	{
		// --- OV7670 CAMERA ---

		// Re-init the camera if the previous housekeeping cycle failed to identify the camera
		if ((status & 0x02) >> 1) OV7670_Init(&hdcmi, &hdma_dcmi, &hi2c1);

		// --- HOUSEKEEPING ---

		status = 0; // Reset housekeeping tracker

		// Check the camera responds with the expected ID
		uint8_t buffer[2];
		uint8_t dev_id[2] = {0x73,0x76};
		OV7670_Read_DevID(buffer);
		for (int i = 0; i < 2; i++)
		{
		  if (buffer[i] != dev_id[i]) status |= 0x02;
		}

		// --- CURRENT SENSE AMPLIFIER ---

		// Grab IV Sensor Data, check whether voltage error, and save to microSD
		CSA_ReadAll(&csa);
		if (csa.bus_voltage < VOLTAGE_ERROR_THRESH_MV) status |= 0x01;

		// --- WRITE TO DATA TO MICROSD ---

		// Start a new log file every MICROSD_TIME_PERIOD_MS
		if (xTaskGetTickCount() > (prev_time + MICROSD_TIME_PERIOD_MS))
		{
		  if (microsd_create_indexed_file(filename) != HAL_OK) status |= 0x08;
		  if (microsd_init_file(filename) != HAL_OK) status |= 0x10;
		  prev_time = xTaskGetTickCount();
		}
		// Append row of data to file
		if (microsd_append_file(filename, csa, status, g_imaging_req) != HAL_OK) status |= 0x20;

		// --- UPDATE RGB LED ---
		#if LED_MODE == LED_ENABLE
			if (status & 0x01) RGB_Error_Fatal(); 				// Voltage too low
			else if ((status & 0x02) >> 1) RGB_Error_Camera();	// Camera unresponsive
			else if ((status & 0x3C) > 0) RGB_Error_microSD();	// microSD unresponsive
			else RGB_Nominal();
		#endif

		osDelay(TASK_TIMEOUT);
	}
  /* USER CODE END housekeepingTask */
}

void imagingTask(void *argument)
{
  /* USER CODE BEGIN imagingTask */

	// Wait for initialisation
	while (!img_store_ready())
	{
		img_store_init();
		osDelay(100);
	}

	#if OPERATIONAL_MODE != NO_MODE
		#if COMPRESSION_MODE == COMPRESSION_ENABLE
		  img_jpeg_init(&hjpeg);
		#endif

		#if IMG_SELFTEST
		  img_selftest_run(pBuffer);
		#endif

		#if OPERATIONAL_MODE == USB_MODE
		  camera_dashboard_operate();

		#elif OPERATIONAL_MODE == SLAVE_MODE
		  camera_capture_continuous(pBuffer);

		#endif

	#else
	  for(;;)
	  {
		  osDelay(osWaitForever);
	  }
	#endif

  /* USER CODE END imagingTask */
}

/* USER CODE BEGIN Header_imageHkReqTask */
/**
* @brief Request an image if none are being requested by FISH
* @param argument: Not used
* @retval None
*/
/* USER CODE END Header_imageHkReqTask */
void imageHkReqTask(void *argument)
{
  /* USER CODE BEGIN imageHkReqTask */

  /* Infinite loop */
  for(;;)
  {
	  if (g_imaging_req.src != IMG_SRC_FISH)
	  {
		  g_imaging_req.buf = 1;
		  g_imaging_req.src = IMG_SRC_C2S;
	  }

	  osDelay(configTICK_RATE_HZ*10); // Wait 10s
  }
  /* USER CODE END imageHkReqTask */
}

 /* MPU Configuration */

void MPU_Config(void)
{
  MPU_Region_InitTypeDef MPU_InitStruct = {0};

  /* Disables the MPU */
  HAL_MPU_Disable();

  /** Initializes and configures the Region and the memory to be protected
  */
  MPU_InitStruct.Enable = MPU_REGION_ENABLE;
  MPU_InitStruct.Number = MPU_REGION_NUMBER0;
  MPU_InitStruct.BaseAddress = 0x60000000;
  MPU_InitStruct.Size = MPU_REGION_SIZE_8MB;
  MPU_InitStruct.SubRegionDisable = 0x00;
  MPU_InitStruct.TypeExtField = MPU_TEX_LEVEL0;
  MPU_InitStruct.AccessPermission = MPU_REGION_FULL_ACCESS;
  MPU_InitStruct.DisableExec = MPU_INSTRUCTION_ACCESS_ENABLE;
  MPU_InitStruct.IsShareable = MPU_ACCESS_SHAREABLE;
  MPU_InitStruct.IsCacheable = MPU_ACCESS_NOT_CACHEABLE;
  MPU_InitStruct.IsBufferable = MPU_ACCESS_NOT_BUFFERABLE;

  HAL_MPU_ConfigRegion(&MPU_InitStruct);
  /* Enables the MPU */
  HAL_MPU_Enable(MPU_PRIVILEGED_DEFAULT);

}

void HAL_TIM_PeriodElapsedCallback(TIM_HandleTypeDef *htim)
{
  if (htim->Instance == TIM1)
  {
    HAL_IncTick();
  }
}

void Error_Handler(void)
{
  __disable_irq();
  while (1)
  {
  }
}
